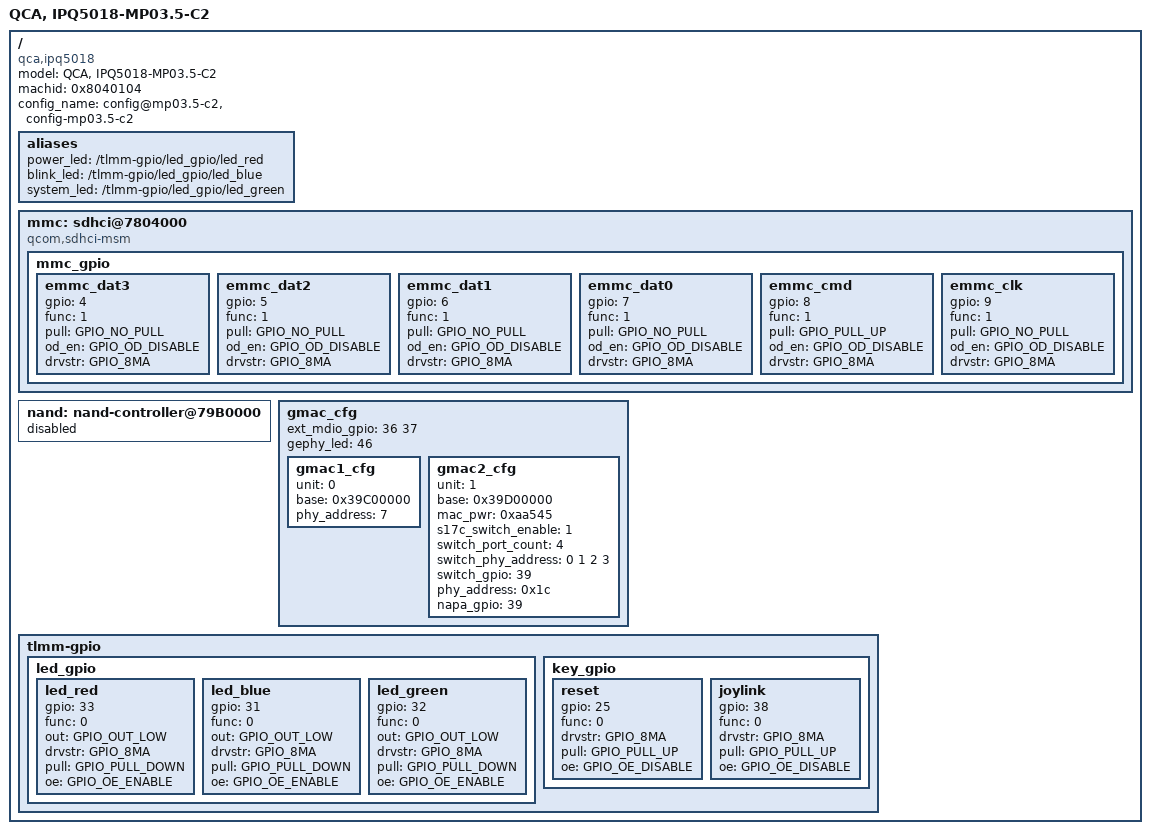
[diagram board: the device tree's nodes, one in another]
/*
 * Copyright (c) 2016-2020, The Linux Foundation. All rights reserved.
 *
 * This program is free software; you can redistribute it and/or modify
 * it under the terms of the GNU General Public License version 2 and
 * only version 2 as published by the Free Software Foundation.
 *
 * This program is distributed in the hope that it will be useful,
 * but WITHOUT ANY WARRANTY; without even the implied warranty of
 * MERCHANTABILITY or FITNESS FOR A PARTICULAR PURPOSE.  See the
 * GNU General Public License for more details.
 */
#include "ipq5018-mp03.5-c1.dts"
/ {
	model ="QCA, IPQ5018-MP03.5-C2";
	compatible = "qca,ipq5018", "qca,ipq5018-mp03.5-c2";
	machid = <0x8040104>;
	config_name = "config@mp03.5-c2", "config-mp03.5-c2";

	aliases {
		power_led = "/tlmm-gpio/led_gpio/led_red";
		blink_led = "/tlmm-gpio/led_gpio/led_blue";
		system_led = "/tlmm-gpio/led_gpio/led_green";
	};

	mmc: sdhci@7804000 {
		compatible = "qcom,sdhci-msm";
		status = "okay";
		mmc_gpio {
			emmc_dat3 {
				gpio = <4>;
				func = <1>;
				pull = <GPIO_NO_PULL>;
				od_en = <GPIO_OD_DISABLE>;
				drvstr = <GPIO_8MA>;
			};
			emmc_dat2 {
				gpio = <5>;
				func = <1>;
				pull = <GPIO_NO_PULL>;
				od_en = <GPIO_OD_DISABLE>;
				drvstr = <GPIO_8MA>;
			};
			emmc_dat1 {
				gpio = <6>;
				func = <1>;
				pull = <GPIO_NO_PULL>;
				od_en = <GPIO_OD_DISABLE>;
				drvstr = <GPIO_8MA>;
			};
			emmc_dat0 {
				gpio = <7>;
				func = <1>;
				pull = <GPIO_NO_PULL>;
				od_en = <GPIO_OD_DISABLE>;
				drvstr = <GPIO_8MA>;
			};
			emmc_cmd{
				gpio = <8>;
				func = <1>;
				pull = <GPIO_PULL_UP>;
				od_en = <GPIO_OD_DISABLE>;
				drvstr = <GPIO_8MA>;
			};
			emmc_clk{
				gpio = <9>;
				func = <1>;
				pull = <GPIO_NO_PULL>;
				od_en = <GPIO_OD_DISABLE>;
				drvstr = <GPIO_8MA>;
			};
		};
	};

	nand: nand-controller@79B0000 {
		status = "disabled";
	};
	gmac_cfg {
		ext_mdio_gpio = <36 37>;
		gephy_led = <46>;

		gmac1_cfg {
			unit = <0>;
			base = <0x39C00000>;
			phy_address = <7>;
		};

		gmac2_cfg {
			unit = <1>;
			base = <0x39D00000>;
			mac_pwr = <0xaa545>;
			s17c_switch_enable = <1>;
			switch_port_count = <4>;
			switch_phy_address = <0 1 2 3>;
			switch_gpio = <39>;
			phy_address = <0x1c>;
			napa_gpio = <39>;
		};
	};
	tlmm-gpio {
		led_gpio {
			led_red {
				gpio = <33>;
				func = <0>;
				out = <GPIO_OUT_LOW>;
				drvstr = <GPIO_8MA>;
				pull = <GPIO_PULL_DOWN>;
				oe = <GPIO_OE_ENABLE>;
			};
			led_blue {
				gpio = <31>;
				func = <0>;
				out = <GPIO_OUT_LOW>;
				drvstr = <GPIO_8MA>;
				pull = <GPIO_PULL_DOWN>;
				oe = <GPIO_OE_ENABLE>;
			};
			led_green {
				gpio = <32>;
				func = <0>;
				out = <GPIO_OUT_LOW>;
				drvstr = <GPIO_8MA>;
				pull = <GPIO_PULL_DOWN>;
				oe = <GPIO_OE_ENABLE>;
			};
		};

		key_gpio {
			reset {
				gpio = <25>;
				func = <0>;
				drvstr = <GPIO_8MA>;
				pull = <GPIO_PULL_UP>;
				oe = <GPIO_OE_DISABLE>;
			};
			joylink {
				gpio = <38>;
				func = <0>;
				drvstr = <GPIO_8MA>;
				pull = <GPIO_PULL_UP>;
				oe = <GPIO_OE_DISABLE>;
			};
		};
	};
};
